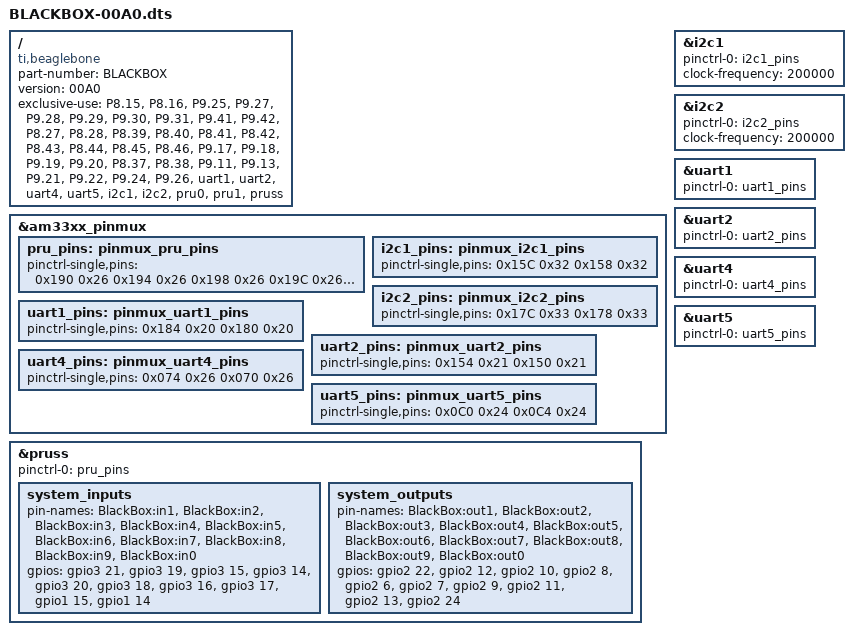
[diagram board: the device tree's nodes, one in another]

//~~~~~~~~~~~~~~~~~~~~~~~~~~~~~~~~~~~~~~~~
//  BLACKBOX.dts
//  Gradient Consulting, LLC
//  Justin M Selfridge
//~~~~~~~~~~~~~~~~~~~~~~~~~~~~~~~~~~~~~~~~


/dts-v1/;
/plugin/;


/ {


    //--  Identification  --//
    compatible   = "ti,beaglebone", "ti,beaglebone-black";
    part-number  = "BLACKBOX";
    version      = "00A0";


    //--  Allocate hardware and pins  --//
    exclusive-use = 


        //--  INPUTS  --//
        "P8.15",
        "P8.16",
        "P9.25",
        "P9.27",
        "P9.28",
        "P9.29",
        "P9.30",
        "P9.31",
        "P9.41",
        "P9.42",

        //--  OUTPUTS  --//
        "P8.27",
        "P8.28",
        "P8.39",
        "P8.40",
        "P8.41",
        "P8.42",
        "P8.43",
        "P8.44",
        "P8.45",
        "P8.46",

        //--  I2C  --//
        "P9.17",
        "P9.18",
        "P9.19",
        "P9.20",

        //--  SERIAL  --//
        "P8.37",
        "P8.38",
        "P9.11",
        "P9.13",
        "P9.21",
        "P9.22",
        "P9.24",
        "P9.26",
/*
|        //--  GPIO  --//
|	"P9.15",
|	"P9.16",
*/

        //--  HARDWARE  --//
        "uart1",
        "uart2",
        "uart4",
        "uart5",
        "i2c1",
        "i2c2",
        "pru0",
        "pru1",
        "pruss";


    //--  Primary fragment  --//
    fragment@0 {
        target = <&am33xx_pinmux>;
        __overlay__ {

            //--  PRU pins  --//
            pru_pins: pinmux_pru_pins {
                pinctrl-single,pins = <

                    //--  PRU0: Input  --//
                    0x190  0x26      //  P9.31 | r31.00 | GPIO.3.14 | MODE 6 | CH.4   //
                    0x194  0x26      //  P9.29 | r31.01 | GPIO.3.15 | MODE 6 | CH.3   //
                    0x198  0x26      //  P9.30 | r31.02 | GPIO.3.16 | MODE 6 | CH.7   //
                    0x19C  0x26      //  P9.28 | r31.03 | GPIO.3.17 | MODE 6 | CH.8   //
                    0x1A0  0x26      //  P9.42 | r31.04 | GPIO.3.18 | MODE 6 | CH.6   //
                    0x1A4  0x26      //  P9.27 | r31.05 | GPIO.3.19 | MODE 6 | CH.2   //
                    0x1A8  0x26      //  P9.41 | r31.06 | GPIO.3.20 | MODE 6 | CH.5   //
                    0x1AC  0x26      //  P9.25 | r31.07 | GPIO.3.21 | MODE 6 | CH.1   //
                    0x038  0x26      //  P8.16 | r31.14 | GPIO.1.14 | MODE 6 | CH.0  //
                    0x03C  0x26      //  P8.15 | r31.15 | GPIO.1.15 | MODE 6 | CH.9  //
                    //0x1B4  0x20      //  Enable P9.41  //
                    //0x164  0x20      //  Enable P9.42  //

                    //--  PRU1: Output  --//
                    0x0A0  0x05      //  P8.45 | r31.00 | GPIO.2.06 | MODE 5 | CH.5  //
                    0x0A4  0x05      //  P8.46 | r31.01 | GPIO.2.07 | MODE 5 | CH.6  //
                    0x0A8  0x05      //  P8.43 | r31.02 | GPIO.2.08 | MODE 5 | CH.4  //
                    0x0AC  0x05      //  P8.44 | r31.03 | GPIO.2.09 | MODE 5 | CH.7  //
                    0x0B0  0x05      //  P8.41 | r31.04 | GPIO.2.10 | MODE 5 | CH.3  //
                    0x0B4  0x05      //  P8.42 | r31.05 | GPIO.2.11 | MODE 5 | CH.8  //
                    0x0B8  0x05      //  P8.39 | r31.06 | GPIO.2.12 | MODE 5 | CH.2  //
                    0x0BC  0x05      //  P8.40 | r31.07 | GPIO.2.13 | MODE 5 | CH.9  //
                    0x0E0  0x05      //  P8.27 | r31.08 | GPIO.2.22 | MODE 5 | CH.1  //
                    0x0E8  0x05      //  P8.28 | r31.10 | GPIO.2.24 | MODE 5 | CH.0  //

                >;
            };

            //--  I2C1 pins  --//
            i2c1_pins: pinmux_i2c1_pins {
                pinctrl-single,pins = <
                    0x15C  0x32      //  P9.17 | I2C1_SCL | MODE 2  //
                    0x158  0x32      //  P9.18 | I2C1_SDA | MODE 2  //
                >;
            };

            //--  I2C2 pins  --//
            i2c2_pins: pinmux_i2c2_pins {
                pinctrl-single,pins = <
                    0x17C  0x33      //  P9.19 | I2C2_SCL | MODE 3  //
                    0x178  0x33      //  P9.20 | I2C2_SDA | MODE 3  //
                >;
            };

            //--  UART1 pins  --//
            uart1_pins: pinmux_uart1_pins {
                pinctrl-single,pins = <
                    0x184  0x20      //  P9.24 | UART1_TX | MODE 0  //
                    0x180  0x20      //  P9.26 | UART1_RX | MODE 0  //
                >;
            };

            //--  UART2 pins  --//
            uart2_pins: pinmux_uart2_pins {
                pinctrl-single,pins = <
                    0x154  0x21      //  P9.21 | UART2_TX | MODE 1  //
                    0x150  0x21      //  P9.22 | UART2_RX | MODE 1  //
                >;
            };

            //--  UART4 pins  --//
            uart4_pins: pinmux_uart4_pins {
                pinctrl-single,pins = <
                    0x074  0x26      //  P9.13 | UART4_TX | MODE 6  //
                    0x070  0x26      //  P9.11 | UART4_RX | MODE 6  //
                >;
            };

            //--  UART5 pins  --//
            uart5_pins: pinmux_uart5_pins {
                pinctrl-single,pins = <
                    0x0C0  0x24      //  P8.37 | UART5_TX | MODE 4  //
                    0x0C4  0x24      //  P8.38 | UART5_RX | MODE 4  //
                >;
            };

/*
|            //--  GPIO pins  --//
|            gpio_pins: pinmux_gpio_pins {
|                pinctrl-single,pins = <
|                    0x040  0x37      //  P9.15 | GPIO1_16 | INPUT | PULL UP | MODE 7  //
|                    0x04C  0x37      //  P9.16 | GPIO1_19 | INPUT | PULL UP | MODE 7  //
|                >;
|            };
*/

        };
    };


    //--  PRU INPUT/OUTPUT  --//
    fragment@1 {
        target = <&pruss>;
        __overlay__ {
            status = "okay";
            pinctrl-names = "default";
            pinctrl-0 = <&pru_pins>;

            system_inputs {
                pin-names = "BlackBox:in1", 
                            "BlackBox:in2", 
                            "BlackBox:in3", 
                            "BlackBox:in4", 
                            "BlackBox:in5", 
                            "BlackBox:in6", 
                            "BlackBox:in7", 
                            "BlackBox:in8", 
                            "BlackBox:in9", 
                            "BlackBox:in0"; 
                gpios = <   &gpio3 21 0    
                            &gpio3 19 0    
                            &gpio3 15 0    
                            &gpio3 14 0    
                            &gpio3 20 0    
                            &gpio3 18 0    
                            &gpio3 16 0    
                            &gpio3 17 0    
                            &gpio1 15 0    
                            &gpio1 14 0  
                        >;
            };

            system_outputs {
                pin-names = "BlackBox:out1", 
                            "BlackBox:out2", 
                            "BlackBox:out3", 
                            "BlackBox:out4", 
                            "BlackBox:out5", 
                            "BlackBox:out6", 
                            "BlackBox:out7", 
                            "BlackBox:out8", 
                            "BlackBox:out9", 
                            "BlackBox:out0";
                gpios = <   &gpio2 22 0   
                            &gpio2 12 0   
                            &gpio2 10 0   
                            &gpio2  8 0   
                            &gpio2  6 0   
                            &gpio2  7 0   
                            &gpio2  9 0   
                            &gpio2 11 0   
                            &gpio2 13 0   
                            &gpio2 24 0  
                        >;
            };

        };
    };

    //--  I2C1  --//
    fragment@11 {
        target = <&i2c1>;
        __overlay__ {
            status = "okay";
            pinctrl-names = "default";
            pinctrl-0 = <&i2c1_pins>;
            clock-frequency = <200000>;  // 400000 
            #address-cells = <1>;
            #size-cells = <0>;
        };
    };

    //--  I2C2  --//
    fragment@12 {
        target = <&i2c2>;
        __overlay__ {
            status = "okay";
            pinctrl-names = "default";
            pinctrl-0 = <&i2c2_pins>;
            clock-frequency = <200000>;  // 400000
            #address-cells = <1>;
            #size-cells = <0>;
        };
    };

    //--  UART1  --//
    fragment@21 {
        target = <&uart1>;
        __overlay__ {
            status = "okay";
            pinctrl-names = "default";
            pinctrl-0 = <&uart1_pins>;
        };
    };

    //--  UART2  --//
    fragment@22 {
        target = <&uart2>;
        __overlay__ {
            status = "okay";
            pinctrl-names = "default";
            pinctrl-0 = <&uart2_pins>;
        };
    };

    //--  UART4  --//
    fragment@24 {
        target = <&uart4>;
        __overlay__ {
            status = "okay";
            pinctrl-names = "default";
            pinctrl-0 = <&uart4_pins>;
        };
    };

    //--  UART5  --//
    fragment@25 {
        target = <&uart5>;
        __overlay__ {
            status = "okay";
            pinctrl-names = "default";
            pinctrl-0 = <&uart5_pins>;
        };
    };

/*
|    //--  GENERAL I/O  --//
|    fragment@2 {
|        target = <&ocp>;
|        __overlay__ {
|	    test_helper: helper {
|	        compatible = "bone-pinmux-helper";
|                status = "okay";
|                pinctrl-names = "default";
|                pinctrl-0 = <&gpio_pins>;
|            };
|        };
|    };
*/

};



